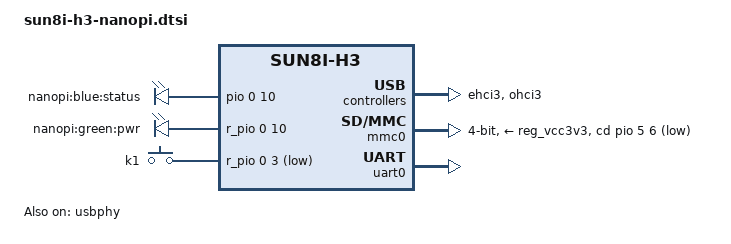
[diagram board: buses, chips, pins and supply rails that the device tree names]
/dts-v1/;
#include "sun8i-h3.dtsi"
#include "sunxi-common-regulators.dtsi"
#include <dt-bindings/gpio/gpio.h>
#include <dt-bindings/input/input.h>
/ {
	aliases {
		serial0 = &uart0;
	};
	chosen {
		stdout-path = "serial0:115200n8";
	};
	leds {
		compatible = "gpio-leds";
		led-0 {
			label = "nanopi:blue:status";
			gpios = <&pio 0 10 GPIO_ACTIVE_HIGH>;
			linux,default-trigger = "heartbeat";
		};
		led-1 {
			label = "nanopi:green:pwr";
			gpios = <&r_pio 0 10 GPIO_ACTIVE_HIGH>;
			default-state = "on";
		};
	};
	gpio-keys {
		compatible = "gpio-keys";
		key-0 {
			label = "k1";
			linux,code = <KEY_POWER>;
			gpios = <&r_pio 0 3 GPIO_ACTIVE_LOW>;
			wakeup-source;
		};
	};
};
&ehci3 {
	status = "okay";
};
&mmc0 {
	bus-width = <4>;
	cd-gpios = <&pio 5 6 GPIO_ACTIVE_LOW>;
	status = "okay";
	vmmc-supply = <&reg_vcc3v3>;
};
&ohci3 {
	status = "okay";
};
&uart0 {
	pinctrl-names = "default";
	pinctrl-0 = <&uart0_pa_pins>;
	status = "okay";
};
&usbphy {
	status = "okay";
};
